# SCB register map
Vendor: Texas Instruments
Peripheral module from a debugger description file (folder UCD3138R064RSM).
Registers are 32-bit, read-only, reset 0x0 unless marked. A register's access mark holds for its fields unless they carry their own. Offsets are as the file gives them; lines under a group give offsets from that group; [hi:lo] are bit positions; {n}, {i} and the like mark numbered series; 'fields as' and 'values as' point back to an identical list; <NAME> marks a mode.

## SCB
0x00 REVIDR reset 0x411FD210 — Provides implementation-specific minor revision information
  [31:0] IMPLEMENTAION_DEFINED — The contents of this field are IMPLEMENTATION DEFINED
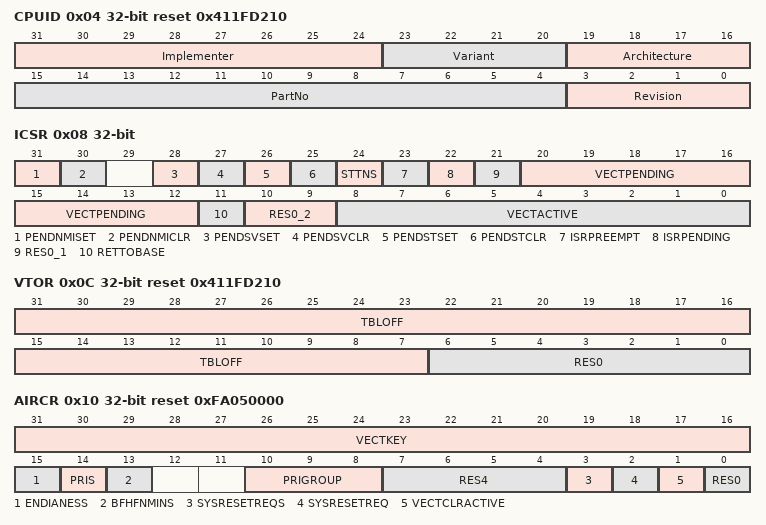
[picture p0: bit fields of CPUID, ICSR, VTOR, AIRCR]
0x04 CPUID reset 0x411FD210 — Provides identification information for the PE, including an implementer code for the device and a device ID number
  [31:24] Implementer — This field must hold an implementer code that has been assigned by ARM
  [23:20] Variant — IMPLEMENTATION DEFINED variant number. Typically, this field is used to distinguish between different product variants, or major revisions of a product
  [19:16] Architecture — Defines the Architecture implemented by the PE
  [15:4] PartNo — IMPLEMENTATION DEFINED primary part number for the device
  [3:0] Revision — IMPLEMENTATION DEFINED revision number for the device
0x08 ICSR access per field — Controls and provides status information for NMI, PendSV, SysTick and interrupts
  [31] PENDNMISET ro — Indicates whether the NMI exception is pending
  [30] PENDNMICLR wo — Allows the NMI exception pend state to be cleared
  [28] PENDSVSET ro — Indicates whether the PendSV `FTSSS exception is pending
  [27] PENDSVCLR wo — Allows the PendSV exception pend state to be cleared `FTSSS
  [26] PENDSTSET ro — Indicates whether the SysTick `FTSSS exception is pending
  [25] PENDSTCLR wo — Allows the SysTick exception pend state to be cleared `FTSSS
  [24] STTNS rw — Controls whether in a single SysTick implementation, the SysTick is Secure or Non-secure
  [23] ISRPREEMPT ro — Indicates whether a pending exception will be serviced on exit from debug halt state
  [22] ISRPENDING ro — Indicates whether an external interrupt, generated by the NVIC, is pending
  [21] RES0_1 ro — Reserved, RES0
  [20:12] VECTPENDING ro — The exception number of the highest priority pending and enabled interrupt
  [11] RETTOBASE ro — In Handler mode, indicates whether there is more than one active exception
  [10:9] RES0_2 ro — Reserved, RES0
  [8:0] VECTACTIVE ro — The exception number of the current executing exception
0x0C VTOR reset 0x411FD210 — Indicates the offset of the vector table base address from memory address 0x00000000
  [31:7] TBLOFF — Bits 31 down to 7 of the vector table base offset.
  [6:0] RES0 — Software should not rely on the value of a reserved. Writing any other value than the reset value may result in undefined behavior.
0x10 AIRCR access per field reset 0xFA050000 — This register is used to determine data endianness, clear all active state information for debug or to recover from a hard failure, execute a system reset, alter the priority grouping position (binary point).
  [31:16] VECTKEY rw — Register key. Writing to this register (AIRCR) requires 0x05FA in VECTKEY. Otherwise the write value is ignored. Read always returns 0xFA05.
  [15] ENDIANESS ro — Data endianness bit 0 Little-endian. 1 Big-endian.
  [14] PRIS ro — Prioritize Secure exceptions. The value of this bit defines whether Secure exception priority boosting is enabled.
  [13] BFHFNMINS rw — BusFault, HardFault, and NMI Non-secure enable. The value of this bit defines whether BusFault and NMI exceptions are Non-secure, and whether exceptions target the Non-secure HardFault exception 0x0 BusFault, HardFault, and NMI are Secure. 0x1 BusFault and NMI are Non-secure and exceptions can target Non-secure HardFault.
  [10:8] PRIGROUP rw — Interrupt priority grouping field. This field determines the split of group priority from subpriority
  [7:4] RES4 ro — Software should not rely on the value of a reserved. Writing any other value than the reset value may result in undefined behavior.
  [3] SYSRESETREQS rw — System reset request Secure only. The value of this bit defines whether the SYSRESETREQ bit is functional for Non-secure use
  [2] SYSRESETREQ wo — System reset request. This bit allows software or a debugger to request a system reset: 0 Do not request a system reset. 1 Request a system reset. This bit is not banked between Security states.
  [1] VECTCLRACTIVE wo — Reserved for Debug use. This bit reads as 0. When writing to the register you must write 0 to this bit, otherwise behavior is UNPREDICTABLE.
  [0] RES0 ro — Software should not rely on the value of a reserved. Writing any other value than the reset value may result in undefined behavior.
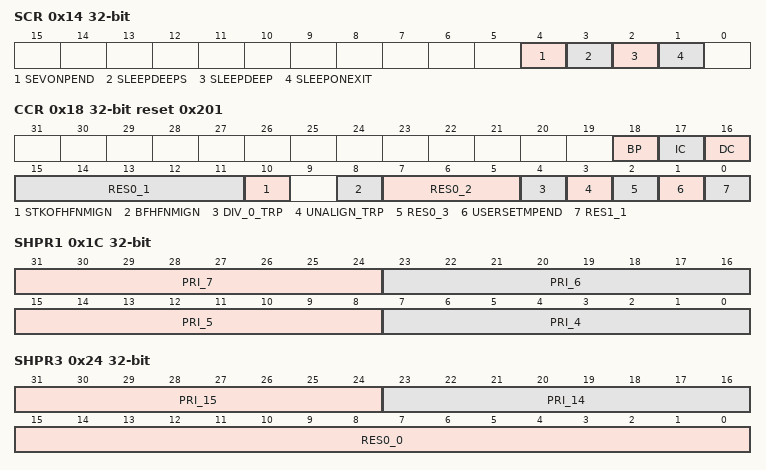
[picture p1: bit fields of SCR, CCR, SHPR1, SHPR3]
0x14 SCR access per field — This register is used for power-management functions, i.e., signaling to the system when the processor can enter a low power state, controlling how the processor enters and exits low power states.
  [4] SEVONPEND rw — Send Event on Pending bit: 0 Only enabled interrupts or events can wakeup the processor, disabled interrupts are excluded. 1 Enabled events and all interrupts, including disabled interrupts, can wakeup the processor. When an event or interrupt enters pending state, the event signal wakes up the processor from WFE. If the processor is not waiting for an event, the event is registered and affects the next WFE. The processor also wakes up on execution of an SEV instruction or an external event. This bit is banked between Security states.
  [3] SLEEPDEEPS rw — Controls whether the SLEEPDEEP bit is only accessible from the Secure state: 0 The SLEEPDEEP bit accessible from both Security states. 1 The SLEEPDEEP bit behaves as RAZ/WI when accessed from the Non-secure state. This bit in only accessible from the Secure state, and behaves as RAZ/WI when accessed from the Nonsecure state. This bit is not banked between Security states.
  [2] SLEEPDEEP rw — Controls whether the processor uses sleep or deep sleep as its low power mode. 0 Sleep. 1 Deep sleep. This bit is not banked between Security states.
  [1] SLEEPONEXIT rw — Indicates sleep-on-exit when returning from Handler mode to Thread mode: 0 Do not sleep when returning to Thread mode. 1 Enter sleep, or deep sleep, on return from an ISR. Setting this bit to 1 enables an interrupt driven application to avoid returning to an empty main application. This bit is banked between Security states.
0x18 CCR access per field reset 0x201 — Sets or returns configuration and control data
  [18] BP ro — Enables program flow prediction `FTSSS
  [17] IC ro — This is a global enable bit for instruction caches in the selected Security state
  [16] DC ro — Enables data caching of all data accesses to Normal memory `FTSSS
  [15:11] RES0_1 ro — Reserved, RES0
  [10] STKOFHFNMIGN rw — Controls the effect of a stack limit violation while executing at a requested priority less than 0
  [8] BFHFNMIGN rw — Determines the effect of precise BusFaults on handlers running at a requested priority less than 0
  [7:5] RES0_2 ro — Reserved, RES0
  [4] DIV_0_TRP rw — Controls the generation of a DIVBYZERO UsageFault when attempting to perform integer division by zero
  [3] UNALIGN_TRP rw — Controls the trapping of unaligned word or halfword accesses
  [2] RES0_3 ro — Reserved, RES0
  [1] USERSETMPEND rw — Determines whether unprivileged accesses are permitted to pend interrupts via the STIR
  [0] RES1_1 ro — Reserved, RES1
0x1C SHPR1 rw — Sets or returns priority for system handlers 4 - 7
  [31:24] PRI_7 — Priority of system handler 7, SecureFault
  [23:16] PRI_6 — Priority of system handler 6, UsageFault
  [15:8] PRI_5 — Priority of system handler 5, BusFault
  [7:0] PRI_4 — Priority of system handler 4, MemManage
0x20 SHPR2 access per field — Sets or returns priority for system handlers 8 - 11
  [31:24] PRI_11 rw — Priority of system handler 11, SVCall
0x24 SHPR3 access per field — Sets or returns priority for system handlers 12 - 15
  [31:24] PRI_15 rw — Priority of system handler 15, SysTick
  [23:16] PRI_14 rw — Priority of system handler 14, PendSV
  [15:0] RES0_0 ro — Reserved, RES0
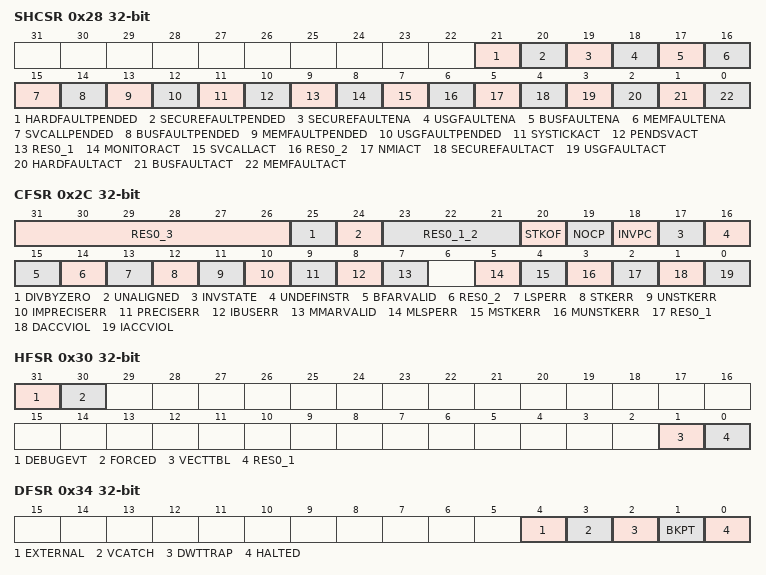
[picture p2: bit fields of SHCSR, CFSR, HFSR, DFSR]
0x28 SHCSR access per field — Provides access to the active and pending status of system exceptions
  [21] HARDFAULTPENDED rw — `IAAMO the pending state of the HardFault exception `CTTSSS
  [20] SECUREFAULTPENDED rw — `IAAMO the pending state of the SecureFault exception
  [19] SECUREFAULTENA rw — `DW the SecureFault exception is enabled
  [18] USGFAULTENA rw — `DW the UsageFault exception is enabled `FTSSS
  [17] BUSFAULTENA rw — `DW the BusFault exception is enabled
  [16] MEMFAULTENA rw — `DW the MemManage exception is enabled `FTSSS
  [15] SVCALLPENDED rw — `IAAMO the pending state of the SVCall exception `FTSSS
  [14] BUSFAULTPENDED rw — `IAAMO the pending state of the BusFault exception
  [13] MEMFAULTPENDED rw — `IAAMO the pending state of the MemManage exception `FTSSS
  [12] USGFAULTPENDED rw — The UsageFault exception is banked between Security states, `IAAMO the pending state of the UsageFault exception `FTSSS
  [11] SYSTICKACT rw — `IAAMO the active state of the SysTick exception `FTSSS
  [10] PENDSVACT rw — `IAAMO the active state of the PendSV exception `FTSSS
  [9] RES0_1 ro — Reserved, RES0
  [8] MONITORACT rw — `IAAMO the active state of the DebugMonitor exception
  [7] SVCALLACT rw — `IAAMO the active state of the SVCall exception `FTSSS
  [6] RES0_2 ro — Reserved, RES0
  [5] NMIACT rw — `IAAMO the active state of the NMI exception
  [4] SECUREFAULTACT rw — `IAAMO the active state of the SecureFault exception
  [3] USGFAULTACT rw — `IAAMO the active state of the UsageFault exception `FTSSS
  [2] HARDFAULTACT rw — Indicates and allows limited modification of the active state of the HardFault exception `FTSSS
  [1] BUSFAULTACT rw — `IAAMO the active state of the BusFault exception
  [0] MEMFAULTACT rw — `IAAMO the active state of the MemManage exception `FTSSS
0x2C CFSR access per field — Contains the three Configurable Fault Status Registers
  [31:26] RES0_3 ro — Reserved, RES0
  [25] DIVBYZERO rw — Sticky flag indicating whether an integer division by zero error has occurred
  [24] UNALIGNED rw — Sticky flag indicating whether an unaligned access error has occurred
  [23:21] RES0_1_2 ro — Reserved, RES0
  [20] STKOF rw — Sticky flag indicating whether a stack overflow error has occurred
  [19] NOCP rw — Sticky flag indicating whether a coprocessor disabled or not present error has occurred
  [18] INVPC rw — Sticky flag indicating whether an integrity check error has occurred
  [17] INVSTATE rw — Sticky flag indicating whether an EPSR.T or EPSR.IT validity error has occurred
  [16] UNDEFINSTR rw — Sticky flag indicating whether an undefined instruction error has occurred
  [15] BFARVALID rw — Indicates validity of the contents of the BFAR register
  [14] RES0_2 ro — Reserved, RES0
  [13] LSPERR rw — Records whether a BusFault occurred during FP lazy state preservation
  [12] STKERR rw — Records whether a derived BusFault occurred during exception entry stacking
  [11] UNSTKERR rw — Records whether a derived BusFault occurred during exception return unstacking
  [10] IMPRECISERR rw — Records whether an imprecise data access error has occurred
  [9] PRECISERR rw — Records whether a precise data access error has occurred
  [8] IBUSERR rw — Records whether a BusFault on an instruction prefetch has occurred
  [7] MMARVALID rw — Indicates validity of the MMFAR register
  [5] MLSPERR rw — Records whether a MemManage fault occurred during FP lazy state preservation
  [4] MSTKERR rw — Records whether a derived MemManage fault occurred during exception entry stacking
  [3] MUNSTKERR rw — Records whether a derived MemManage fault occurred during exception return unstacking
  [2] RES0_1 ro — Reserved, RES0
  [1] DACCVIOL rw — Records whether a data access violation has occurred
  [0] IACCVIOL rw — Records whether an instruction related memory access violation has occurred
0x30 HFSR access per field — Shows the cause of any HardFaults
  [31] DEBUGEVT rw — Indicates when a Debug event has occurred
  [30] FORCED rw — Indicates that a fault with configurable priority has been escalated to a HardFault exception, because it could not be made active, because of priority, or because it was disabled
  [1] VECTTBL rw — Indicates when a fault has occurred because of a vector table read error on exception processing
  [0] RES0_1 ro — Reserved, RES0
0x34 DFSR access per field — Shows which debug event occurred
  [4] EXTERNAL rw — Sticky flag indicating whether an External debug request debug event has occurred
  [3] VCATCH rw — Sticky flag indicating whether a Vector catch debug event has occurred
  [2] DWTTRAP rw — Sticky flag indicating whether a Watchpoint debug event has occurred
  [1] BKPT rw — Sticky flag indicating whether a Breakpoint debug event has occurred
  [0] HALTED rw — Sticky flag indicating that a Halt request debug event or Step debug event has occurred
0x38 MMFAR rw — Shows the address of the memory location that caused an MPU fault
  [31:0] ADDRESS — This register is updated with the address of a location that produced a MemManage fault. The MMFSR shows the cause of the fault, and whether this field is valid. This field is valid only when MMFSR.MMARVALID is set, otherwise it is UNKNOWN
0x3C BFAR rw — Shows the address associated with a precise data access BusFault
  [31:0] ADDRESS — This register is updated with the address of a location that produced a BusFault. The BFSR shows the reason for the fault. This field is valid only when BFSR.BFARVALID is set, otherwise it is UNKNOWN
0x40 AFSR access per field — This register is used to determine additional system fault information to software. Single-cycle high level on an auxiliary faults is latched as one. The bit can only be cleared by writing a one to the corresponding bit. Auxiliary fault inputs to the CPU are tied to 0.
  [0] IMPDEF rw — Implementation defined. The bits map directly onto the signal assignment to the auxiliary fault inputs. Tied to 0
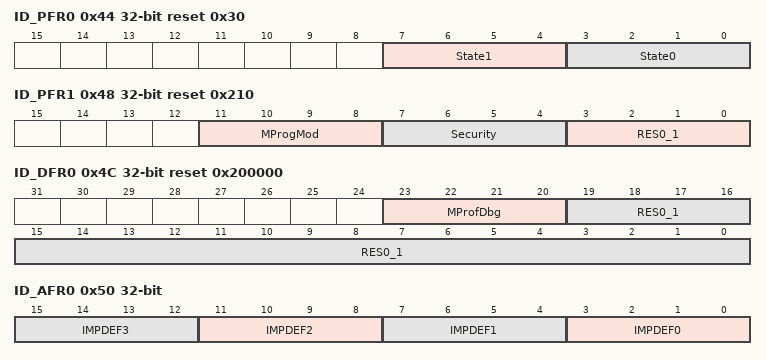
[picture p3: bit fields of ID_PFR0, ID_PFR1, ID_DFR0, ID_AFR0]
0x44 ID_PFR0 reset 0x30 — Gives top-level information about the instruction set supported by the PE
  [7:4] State1 — T32 instruction set support
  [3:0] State0 — A32 instruction set support
0x48 ID_PFR1 reset 0x210 — Gives information about the programmers' model and Extensions support
  [11:8] MProgMod — Identifies support for the M-Profile programmers' model support
  [7:4] Security — Identifies whether the Security Extension is implemented
  [3:0] RES0_1 — Reserved, RES0
0x4C ID_DFR0 reset 0x200000 — Provides top level information about the debug system
  [23:20] MProfDbg — Indicates the supported M-profile debug architecture
  [19:0] RES0_1 — Reserved, RES0
0x50 ID_AFR0 — Provides information about the IMPLEMENTATION DEFINED features of the PE
  [4n+3:4n] IMPDEF{n} (n=0..3) — IMPLEMENTATION DEFINED meaning
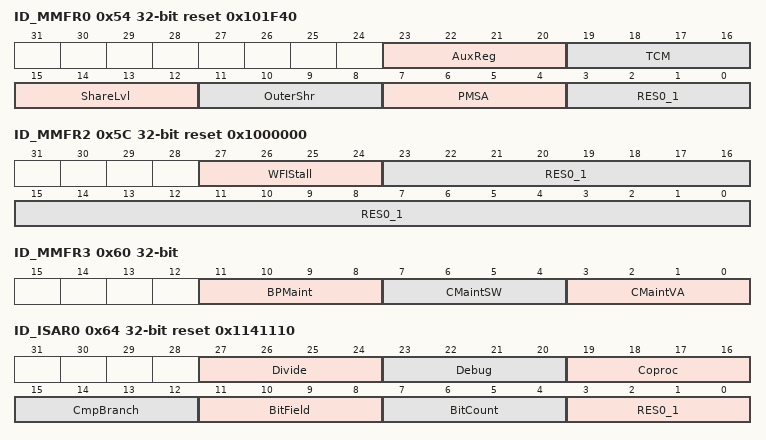
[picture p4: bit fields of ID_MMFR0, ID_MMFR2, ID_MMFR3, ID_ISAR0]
0x54 ID_MMFR0 reset 0x101F40 — Provides information about the implemented memory model and memory management support
  [23:20] AuxReg — Indicates support for Auxiliary Control Registers
  [19:16] TCM — Indicates support for tightly coupled memories (TCMs)
  [15:12] ShareLvl — Indicates the number of shareability levels implemented
  [11:8] OuterShr — Indicates the outermost shareability domain implemented
  [7:4] PMSA — Indicates support for the protected memory system architecture (PMSA)
  [3:0] RES0_1 — Reserved, RES0
0x58 ID_MMFR1 — Provides information about the implemented memory model and memory management support
0x5C ID_MMFR2 reset 0x1000000 — Provides information about the implemented memory model and memory management support
  [27:24] WFIStall — Indicates the support for Wait For Interrupt (WFI) stalling
  [23:0] RES0_1 — Reserved, RES0
0x60 ID_MMFR3 — Provides information about the implemented memory model and memory management support
  [11:8] BPMaint — Indicates the supported branch predictor maintenance
  [7:4] CMaintSW — Indicates the supported cache maintenance operations by set/way
  [3:0] CMaintVA — Indicates the supported cache maintenance operations by address
0x64 ID_ISAR0 reset 0x1141110 — Provides information about the instruction set implemented by the PE
  [27:24] Divide — Indicates the supported Divide instructions
  [23:20] Debug — Indicates the implemented Debug instructions
  [19:16] Coproc — Indicates the supported Coprocessor instructions
  [15:12] CmpBranch — Indicates the supported combined Compare and Branch instructions
  [11:8] BitField — Indicates the supported bit field instructions
  [7:4] BitCount — Indicates the supported bit count instructions
  [3:0] RES0_1 — Reserved, RES0
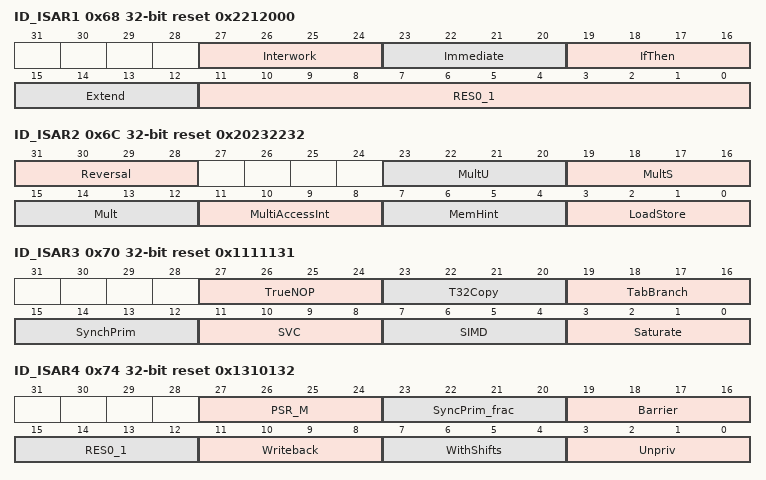
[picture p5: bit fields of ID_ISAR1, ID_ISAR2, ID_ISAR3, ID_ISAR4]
0x68 ID_ISAR1 reset 0x2212000 — Provides information about the instruction set implemented by the PE
  [27:24] Interwork — Indicates the implemented Interworking instructions
  [23:20] Immediate — Indicates the implemented for data-processing instructions with long immediates
  [19:16] IfThen — Indicates the implemented If-Then instructions
  [15:12] Extend — Indicates the implemented Extend instructions
  [11:0] RES0_1 — Reserved, RES0
0x6C ID_ISAR2 reset 0x20232232 — Provides information about the instruction set implemented by the PE
  [31:28] Reversal — Indicates the implemented Reversal instructions
  [23:20] MultU — Indicates the implemented advanced unsigned Multiply instructions
  [19:16] MultS — Indicates the implemented advanced signed Multiply instructions
  [15:12] Mult — Indicates the implemented additional Multiply instructions
  [11:8] MultiAccessInt — Indicates the support for interruptible multi-access instructions
  [7:4] MemHint — Indicates the implemented Memory Hint instructions
  [3:0] LoadStore — Indicates the implemented additional load/store instructions
0x70 ID_ISAR3 reset 0x1111131 — Provides information about the instruction set implemented by the PE
  [27:24] TrueNOP — Indicates the implemented true NOP instructions
  [23:20] T32Copy — Indicates the support for T32 non flag-setting MOV instructions
  [19:16] TabBranch — Indicates the implemented Table Branch instructions
  [15:12] SynchPrim — Used in conjunction with ID_ISAR4.SynchPrim_frac to indicate the implemented Synchronization Primitive instructions
  [11:8] SVC — Indicates the implemented SVC instructions
  [7:4] SIMD — Indicates the implemented SIMD instructions
  [3:0] Saturate — Indicates the implemented saturating instructions
0x74 ID_ISAR4 reset 0x1310132 — Provides information about the instruction set implemented by the PE
  [27:24] PSR_M — Indicates the implemented M profile instructions to modify the PSRs
  [23:20] SyncPrim_frac — Used in conjunction with ID_ISAR3.SynchPrim to indicate the implemented Synchronization Primitive instructions
  [19:16] Barrier — Indicates the implemented Barrier instructions
  [15:12] RES0_1 — Reserved, RES0
  [11:8] Writeback — Indicates the support for writeback addressing modes
  [7:4] WithShifts — Indicates the support for writeback addressing modes
  [3:0] Unpriv — Indicates the implemented unprivileged instructions
0x78 ID_ISAR5 — Provides information about the instruction set implemented by the PE
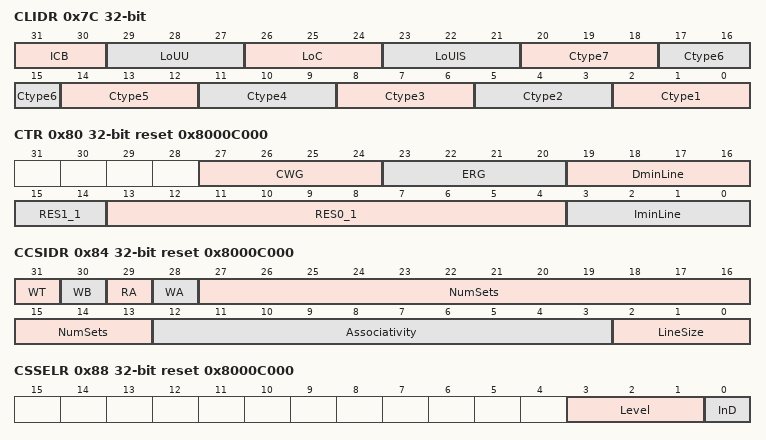
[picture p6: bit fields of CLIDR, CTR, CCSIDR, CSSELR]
0x7C CLIDR — Identifies the type of caches implemented and the level of coherency and unification
  [31:30] ICB — This field indicates the boundary between inner and outer domain
    3=L3 (L3 cache is the highest inner level); 2=L2 (L2 cache is the highest inner level); 1=L1 (L1 cache is the highest inner level); 0=NA (Not disclosed in this mechanism)
  [29:27] LoUU — This field indicates the Level of Unification Uniprocessor for the cache hierarchy
  [26:24] LoC — This field indicates the Level of Coherence for the cache hierarchy
  [23:21] LoUIS — Enables Non-secure access to coprocessor CP0
  [3n-1:3n-3] Ctype{n} (n=1..7) — Cache type field {n}. Indicates the type of cache implemented at level {n}.
    4=BOTH_UNIFIED (Unified cache); 3=BOTH_SEP (Separate instruction and data caches); 2=DATA (Data cache only); 1=INSTR (Instruction cache only); 0=NO_CACHE
0x80 CTR reset 0x8000C000 — The CTR provides information about the architecture of the currently selected cache
  [27:24] CWG — Log2 of the number of words of the maximum size of memory that can be overwritten as a result of the eviction of a cache entry that has had a memory location in it modified
  [23:20] ERG — Log2 of the number of words of the maximum size of the reservation granule that has been implemented for the Load-Exclusive and Store-Exclusive instructions
  [19:16] DminLine — Log2 of the number of words in the smallest cache line of all the data caches and unified caches that are controlled by the PE
  [15:14] RES1_1 — Reserved, RES1
  [13:4] RES0_1 — Reserved, RES0
  [3:0] IminLine — Log2 of the number of words in the smallest cache line of all the instruction caches that are controlled by the PE
0x84 CCSIDR reset 0x8000C000 — Provides information about the architecture of the caches. CCSIDR is RES0 if CLIDR is zero.
  [31] WT — Indicates whether the currently selected cache level supports Write-Through
    1=Supported; 0=NOT_SUPPORTED
  [30] WB — Indicates whether the currently selected cache level supports Write-Back
    1=Supported; 0=NOT_SUPPORTED
  [29] RA — Indicates whether the currently selected cache level supports read-allocation
    1=Supported; 0=NOT_SUPPORTED
  [28] WA — Indicates whether the currently selected cache level supports write-allocation
    1=Supported; 0=NOT_SUPPORTED
  [27:13] NumSets — Indicates (Number of sets in the currently selected cache) - 1. Therefore, a value of 0 indicates that 1 is set in the cache. The number of sets does not have to be a power of 2
  [12:3] Associativity — Indicates (Associativity of cache) - 1. A value of 0 indicates an associativity of 1. The associativity does not have to be a power of 2
  [2:0] LineSize — Indicates (Log2(Number of words per line in the currently selected cache)) - 2.
0x88 CSSELR reset 0x8000C000 — Selects the current Cache Size ID Register, CCSIDR, by specifying the required cache level and the cache type (either instruction or data cache)
  [3:1] Level — Selects which cache level is to be identified. Permitted values are from 0b000, indicating Level 1 cache, to 0b110 indicating Level 7 cache
    {v}=L{v+1} (Level {v+1} cache) (v=0..6)
  [0] InD — Selects whether the instruction or the data cache is to be identified
    1=INSTR (Instruction cache); 0=DATA (Data or unified cache)
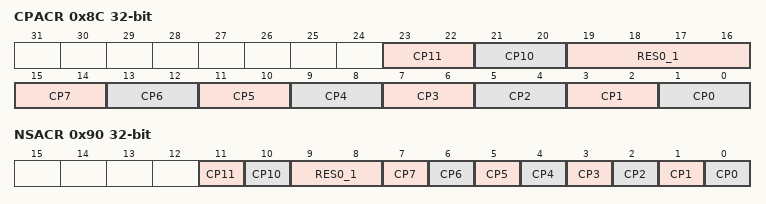
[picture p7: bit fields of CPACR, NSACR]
0x8C CPACR access per field — Specifies the access privileges for coprocessors and the FP Extension
  [23:22] CP11 rw — The value in this field is ignored. If the implementation does not include the FP Extension, this field is RAZ/WI. If the value of this bit is not programmed to the same value as the CP10 field, then the value is UNKNOWN
  [21:20] CP10 rw — Defines the access rights for the floating-point functionality
  [19:16] RES0_1 ro — Reserved, RES0
  [2n+1:2n] CP{n} rw (n=0..7) — Controls access privileges for coprocessor {n}
0x90 NSACR access per field — Defines the Non-secure access permissions for both the FP Extension and coprocessors CP0 to CP7
  [11] CP11 rw — Enables Non-secure access to the Floating-point Extension
  [10] CP10 rw — Enables Non-secure access to the Floating-point Extension
  [9:8] RES0_1 ro — Reserved, RES0
  [n] CP{n} rw (n=0..7) — Enables Non-secure access to coprocessor CP{n}
